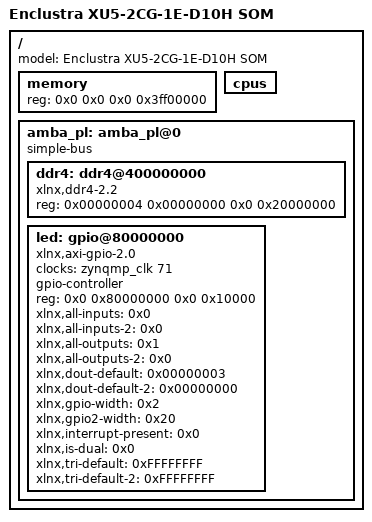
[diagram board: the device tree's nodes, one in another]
#include "zynqmp.dtsi"
#include "zynqmp-clk-ccf.dtsi"
#include "zynqmp_enclustra_common.dtsi"
#include "zynqmp_enclustra_mercury_xu5.dtsi"

/ {
	model = "Enclustra XU5-2CG-1E-D10H SOM";

	memory {
		device_type = "memory";
		reg = <0x0 0x0 0x0 0x3ff00000>;
	};

	cpus {
		/delete-node/ cpu@2 ;
		/delete-node/ cpu@3 ;
	};

/******************** PL entries **********************/

	amba_pl: amba_pl@0 {
		#address-cells = <2>;
		#size-cells = <2>;
		compatible = "simple-bus";
		ranges ;
		ddr4: ddr4@400000000 {
			compatible = "xlnx,ddr4-2.2";
			reg = <0x00000004 0x00000000 0x0 0x20000000>;
		};
		led: gpio@80000000 {
			#gpio-cells = <3>;
			clock-names = "s_axi_aclk";
			clocks = <&zynqmp_clk 71>;
			compatible = "xlnx,axi-gpio-2.0", "xlnx,xps-gpio-1.00.a";
			gpio-controller ;
			reg = <0x0 0x80000000 0x0 0x10000>;
			xlnx,all-inputs = <0x0>;
			xlnx,all-inputs-2 = <0x0>;
			xlnx,all-outputs = <0x1>;
			xlnx,all-outputs-2 = <0x0>;
			xlnx,dout-default = <0x00000003>;
			xlnx,dout-default-2 = <0x00000000>;
			xlnx,gpio-width = <0x2>;
			xlnx,gpio2-width = <0x20>;
			xlnx,interrupt-present = <0x0>;
			xlnx,is-dual = <0x0>;
			xlnx,tri-default = <0xFFFFFFFF>;
			xlnx,tri-default-2 = <0xFFFFFFFF>;
		};
	};

/******************** PL entries **********************/

};
